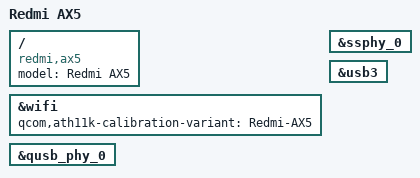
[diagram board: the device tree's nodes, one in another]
// SPDX-License-Identifier: GPL-2.0-or-later OR MIT

/dts-v1/;

#include "ipq6018-xiaomi.dtsi"

/ {
	model = "Redmi AX5";
	compatible = "redmi,ax5", "qcom,ipq6018";
};

&wifi {
	qcom,ath11k-calibration-variant = "Redmi-AX5";
};

&qusb_phy_0 {
	status = "ok";
};

&ssphy_0 {
	status = "ok";
};

&usb3 {
	status = "ok";
};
